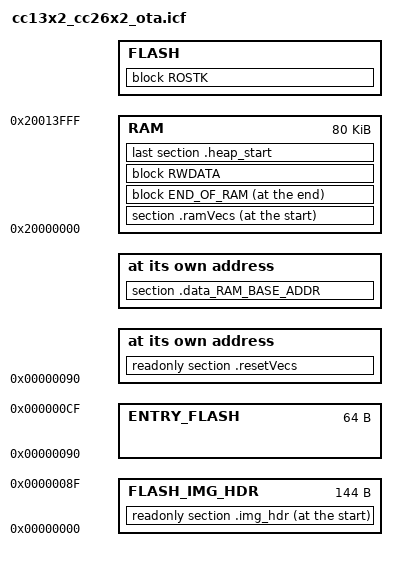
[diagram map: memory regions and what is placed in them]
/******************************************************************************

 @file  cc13x2_cc26x2.icf

 @brief IAR Linker configuration file for cc13x2_cc26x2

 Group: WCS LPC
 Target Device: cc13x2_cc26x2

 ******************************************************************************

 Copyright (c) 2016-2018, Texas Instruments Incorporated
 All rights reserved.

 Redistribution and use in source and binary forms, with or without
 modification, are permitted provided that the following conditions
 are met:

 *  Redistributions of source code must retain the above copyright
    notice, this list of conditions and the following disclaimer.

 *  Redistributions in binary form must reproduce the above copyright
    notice, this list of conditions and the following disclaimer in the
    documentation and/or other materials provided with the distribution.

 *  Neither the name of Texas Instruments Incorporated nor the names of
    its contributors may be used to endorse or promote products derived
    from this software without specific prior written permission.

 THIS SOFTWARE IS PROVIDED BY THE COPYRIGHT HOLDERS AND CONTRIBUTORS "AS IS"
 AND ANY EXPRESS OR IMPLIED WARRANTIES, INCLUDING, BUT NOT LIMITED TO,
 THE IMPLIED WARRANTIES OF MERCHANTABILITY AND FITNESS FOR A PARTICULAR
 PURPOSE ARE DISCLAIMED. IN NO EVENT SHALL THE COPYRIGHT OWNER OR
 CONTRIBUTORS BE LIABLE FOR ANY DIRECT, INDIRECT, INCIDENTAL, SPECIAL,
 EXEMPLARY, OR CONSEQUENTIAL DAMAGES (INCLUDING, BUT NOT LIMITED TO,
 PROCUREMENT OF SUBSTITUTE GOODS OR SERVICES; LOSS OF USE, DATA, OR PROFITS;
 OR BUSINESS INTERRUPTION) HOWEVER CAUSED AND ON ANY THEORY OF LIABILITY,
 WHETHER IN CONTRACT, STRICT LIABILITY, OR TORT (INCLUDING NEGLIGENCE OR
 OTHERWISE) ARISING IN ANY WAY OUT OF THE USE OF THIS SOFTWARE,
 EVEN IF ADVISED OF THE POSSIBILITY OF SUCH DAMAGE.

 *****************************************************************************/

////////////////////////////////////////////////////////////////////////////////
// Memory Sizes
////////////////////////////////////////////////////////////////////////////////
define symbol FLASH_BASE            = 0x00000000;
define symbol RAM_BASE              = 0x20000000;
define symbol ROM_BASE              = 0x10000000;

define symbol RAM_SIZE            = 0x00014000; // 80K
define symbol FLASH_SIZE          = 0x00058000; // 352K
define symbol ROM_SIZE            = 0x00040000; // 256K

////////////////////////////////////////////////////////////////////////////////
// Memory Definitions
////////////////////////////////////////////////////////////////////////////////

////////////////////////////////////////////////////////////////////////////////

// RAM
//

define symbol RAM_START = RAM_BASE;
define symbol RAM_END = RAM_START+RAM_SIZE-1;

////////////////////////////////////////////////////////////////////////////////
// Flash
//
define symbol WORD_SIZE             = 4;

define symbol PAGE_SIZE           = 0x2000;
export symbol PAGE_SIZE;

define symbol FLASH_MEM_ALIGN     = WORD_SIZE;

define symbol FLASH_START           = FLASH_BASE;


// OAD specific

if ( isdefinedsymbol(SECURITY) )
{
  define symbol OAD_HDR_SIZE    = 0x90; // linker needs word alignment.
}
else
{
  define symbol OAD_HDR_SIZE    = 0xA8; // linker needs word alignment.
}
define symbol OAD_HDR_START   = FLASH_START;
define symbol OAD_HDR_END     = OAD_HDR_START + OAD_HDR_SIZE - 1;

define symbol ENTRY_SIZE      = 0x40;
define symbol ENTRY_START     = OAD_HDR_END + 1;
define symbol ENTRY_END       = ENTRY_START + ENTRY_SIZE - 1;

define symbol APP_START       = ENTRY_END + 1;

define symbol NUM_RESERVED_PAGES    = 1;  /*last page i define in FLASH_LAST_PAGE */
define symbol RESERVED_SIZE         = (NUM_RESERVED_PAGES * PAGE_SIZE);

define symbol FLASH_END             = FLASH_START + FLASH_SIZE - RESERVED_SIZE - 1;


////////////////////////////////////////////////////////////////////////////////
// Stack
//

define symbol STACK_SIZE          = 0x400;
define symbol STACK_START         = RAM_END + 1;
define symbol STACK_END           = STACK_START - STACK_SIZE;
//
define symbol STACK_TOP           = RAM_END + 1;
export symbol STACK_TOP;

////////////////////////////////////////////////////////////////////////////////
// Flash Interrupt Vector Table
//

define symbol INTVEC_NUM_ENTRIES  = 50 + 1; // first entry is stack location
define symbol INTVEC_SIZE         = INTVEC_NUM_ENTRIES + 4;

////////////////////////////////////////////////////////////////////////////////
// Memory Regions
////////////////////////////////////////////////////////////////////////////////

define memory mem with size = 4G;

define region RAM                 = mem:[from RAM_START   to RAM_END];
define region FLASH               = mem:[from APP_START to FLASH_END];
define region FLASH_IMG_HDR       = mem:[from OAD_HDR_START  to OAD_HDR_END];
define region ENTRY_FLASH         = mem:[from ENTRY_START    to ENTRY_END];

////////////////////////////////////////////////////////////////////////////////
// Memory Placement
////////////////////////////////////////////////////////////////////////////////


// Flash OAD Image Header
place at start of FLASH_IMG_HDR { readonly section .img_hdr };
keep                            { readonly section .img_hdr };

// Interrupt Vector Table
place at address mem:ENTRY_START { readonly section .resetVecs };
keep                             { readonly section .resetVecs };

define block ROSTK with alignment=WORD_SIZE{ ro };

// All other pieces of codes:
place in FLASH {block ROSTK };

// RAM Vector Table
place at start of RAM { section .ramVecs };

// Runtime Stack
define block CSTACK with alignment = 8, size = STACK_SIZE { section .stack };

if (isdefinedsymbol(ROM_TIMACDataAddr)) {
    place at address mem:ROM_TIMACDataAddr {section .data_RAM_BASE_ADDR };
}

define block RWDATA { rw };

define section .heap_start            { public heapStart: };
define section .heap_end              { public heapEnd: };
define block   HEAP_END with size = 1 { section .heap_end };

define block END_OF_RAM with fixed order {
                                        block HEAP_END,
                                        block CSTACK
                                      };
place at end of RAM { block END_OF_RAM };

place in RAM { block RWDATA,
               last section .heap_start};
	       
////////////////////////////////////////////////////////////////////////////////
// Initialization
////////////////////////////////////////////////////////////////////////////////

initialize by copy { readwrite };

do not initialize
{
  section .noinit,
  section .stack,
};

////////////////////////////////////////////////////////////////////////////////
// The USE_TIRTOS_ROM symbol is defined internally in the build flow (using
// --config_def USE_TIRTOS_ROM=1) for TI-RTOS applications whose appBLE.cfg file
// specifies to use the ROM.
//
if (isdefinedsymbol(USE_TIRTOS_ROM)) {
     include "TIRTOS_ROM.icf";
}
